VERSION "0.1"

BS_:

BU_:

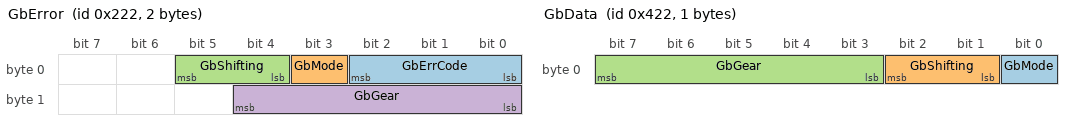
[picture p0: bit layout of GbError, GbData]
BO_ 546 GbError: 2 Vector__XXX
 SG_ GbErrCode : 0|3@1+ (1,0) [0|1] "" Vector__XXX
 SG_ GbMode : 3|1@1+ (1,0) [0|1] "" Vector__XXX
 SG_ GbShifting : 4|2@1+ (1,0) [0|3] "" Vector__XXX
 SG_ GbGear : 8|5@1+ (1,0) [0|16] "" Vector__XXX

BO_ 1058 GbData: 1 Vector__XXX
 SG_ GbMode : 0|1@1+ (1,0) [0|1] "" Vector__XXX
 SG_ GbShifting : 1|2@1+ (1,0) [0|3] "" Vector__XXX
 SG_ GbGear : 3|5@1+ (1,0) [0|16] "" Vector__XXX

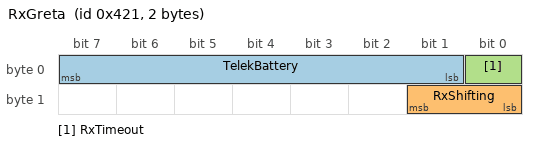
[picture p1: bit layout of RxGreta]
BO_ 1057 RxGreta: 2 Vector__XXX
 SG_ TelekBattery : 1|7@1+ (1,0) [0|100] "%" Vector__XXX
 SG_ RxShifting : 8|2@1+ (1,0) [0|3] "" Vector__XXX
 SG_ RxTimeout : 0|1@1+ (1,0) [0|1] "" Vector__XXX

BO_ 1089 BobSrmPower: 2 Vector__XXX
 SG_ SrmPower : 0|16@1+ (0.1,0) [0|1000] "W" Vector__XXX

BO_ 1090 BobSrmCadence: 2 Vector__XXX
 SG_ SrmCadence : 0|16@1+ (0.1,0) [0|1000] "rpm" Vector__XXX

BO_ 1091 BobHsSpeed: 2 Vector__XXX
 SG_ HsSpeed : 0|16@1+ (0.01,0) [0|200] "km/h" Vector__XXX

BO_ 1092 BobHsDisplacement: 2 Vector__XXX
 SG_ HsDisplacement : 0|16@1+ (0.1,1) [0|9000] "m" Vector__XXX

BO_ 1094 BobHR: 1 Vector__XXX
 SG_ HeartRate : 0|8@1+ (1,0) [0|250] "bpm" Vector__XXX
